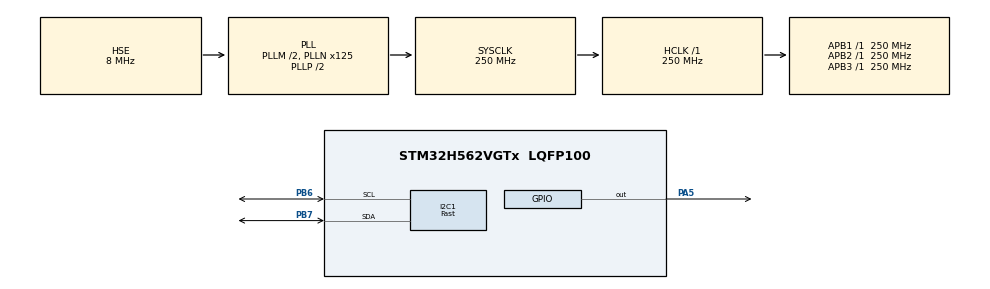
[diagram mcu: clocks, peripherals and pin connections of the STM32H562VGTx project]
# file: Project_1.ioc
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BOOTPATH.BootPathName=LEGACY
BOOTPATH.UserSelectedBootPath=LEGACY
CORTEX_M33_NS.Number-Cortex_Memory_Protection_Unit_Region0_OTP_RO_AREAS_Settings=MPU_REGION_NUMBER0
CORTEX_M33_NS.default_mode_Activation=1
CORTEX_M33_NS.userName=CORTEX_M33
I2C1.I2C_Speed_Mode=I2C_Fast
I2C1.Timing=0x10C043E5
Mcu.Family=STM32H5
Mcu.Name=STM32H562VGTx
Mcu.Package=LQFP100
NVIC.PriorityGroup=NVIC_PRIORITYGROUP_4
PA13(JTMS/SWDIO).Mode=Trace_Asynchronous_SW
PA13(JTMS/SWDIO).Signal=DEBUG_JTMS-SWDIO
PA14(JTCK/SWCLK).Mode=Trace_Asynchronous_SW
PA14(JTCK/SWCLK).Signal=DEBUG_JTCK-SWCLK
PA5.GPIO_Speed=GPIO_SPEED_FREQ_MEDIUM
PA5.Signal=GPIO_Output
PB3(JTDO/TRACESWO).Mode=Trace_Asynchronous_SW
PB3(JTDO/TRACESWO).Signal=DEBUG_JTDO-SWO
PB6.Mode=I2C
PB6.Signal=I2C1_SCL
PB7.Mode=I2C
PB7.Signal=I2C1_SDA
PH0-OSC_IN(PH0).Mode=HSE-External-Oscillator
PH0-OSC_IN(PH0).Signal=RCC_OSC_IN
PH1-OSC_OUT(PH1).Mode=HSE-External-Oscillator
PH1-OSC_OUT(PH1).Signal=RCC_OSC_OUT
ProjectManager.HeapSize=0x2000
ProjectManager.StackSize=0x4000
ProjectManager.TargetToolchain=STM32CubeIDE
RCC.ADCFreq_Value=250000000
RCC.AHBFreq_Value=250000000
RCC.APB1Freq_Value=250000000
RCC.APB1TimFreq_Value=250000000
RCC.APB2Freq_Value=250000000
RCC.APB2TimFreq_Value=250000000
RCC.APB3Freq_Value=250000000
RCC.CSI_VALUE=4000000
RCC.CortexFreq_Value=250000000
RCC.EPOD_VALUE=8000000
RCC.HCLKFreq_Value=250000000
RCC.HSE_VALUE=8000000
RCC.HSI48_VALUE=48000000
RCC.HSI_VALUE=64000000
RCC.LSE_VALUE=32768
RCC.LSIRC_VALUE=32000
RCC.PLLM=2
RCC.PLLN=125
RCC.PLLSourceVirtual=RCC_PLL1_SOURCE_HSE
RCC.SYSCLKFreq_VALUE=250000000
RCC.SYSCLKSource=RCC_SYSCLKSOURCE_PLLCLK
RCC.USBFreq_Value=48000000
RCC.VCOOutputFreq_Value=500000000
VP_BOOTPATH_VS_BOOTPATH.Mode=BP_Activate
VP_CORTEX_M33_NS_VS_Hclk.Mode=Hclk_Mode
VP_ICACHE_VS_ICACHE.Mode=DirectMappedCache
VP_MEMORYMAP_VS_MEMORYMAP.Mode=CurAppReg
VP_PWR_VS_LPOM.Mode=PowerOptimisation
VP_PWR_VS_SECSignals.Mode=Security/Privilege
board=custom

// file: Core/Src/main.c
/* USER CODE BEGIN Header */
/**
  ******************************************************************************
  * @file           : main.c
  * @brief          : Main program body
  ******************************************************************************
  * @attention
  *
  * Copyright (c) 2026 STMicroelectronics.
  * All rights reserved.
  *
  * This software is licensed under terms that can be found in the LICENSE file
  * in the root directory of this software component.
  * If no LICENSE file comes with this software, it is provided AS-IS.
  *
  ******************************************************************************
  */
/* USER CODE END Header */
#include "main.h"

/* USER CODE BEGIN Includes */
#include "bobik/bobik.h"
/* USER CODE END Includes */

I2C_HandleTypeDef hi2c1;

void SystemClock_Config(void);
static void MPU_Config(void);
static void MX_GPIO_Init(void);
static void MX_ICACHE_Init(void);
static void MX_I2C1_Init(void);

int main(void)
{

  /* MCU Configuration--------------------------------------------------------*/

  /* MPU Configuration--------------------------------------------------------*/
  MPU_Config();

  /* Reset of all peripherals, Initializes the Flash interface and the Systick. */
  HAL_Init();

  /* Configure the system clock */
  SystemClock_Config();

  /* Initialize all configured peripherals */
  MX_GPIO_Init();
  MX_ICACHE_Init();
  MX_I2C1_Init();
  /* USER CODE BEGIN 2 */
  bobik_start();
  oled_init();
  oled_fill();
  /* USER CODE END 2 */

  /* Infinite loop */
  while (1)
  {

  }
}

void SystemClock_Config(void)
{
  RCC_OscInitTypeDef RCC_OscInitStruct = {0};
  RCC_ClkInitTypeDef RCC_ClkInitStruct = {0};

  /** Configure the main internal regulator output voltage
  */
  __HAL_PWR_VOLTAGESCALING_CONFIG(PWR_REGULATOR_VOLTAGE_SCALE0);

  while(!__HAL_PWR_GET_FLAG(PWR_FLAG_VOSRDY)) {}

  /** Initializes the RCC Oscillators according to the specified parameters
  * in the RCC_OscInitTypeDef structure.
  */
  RCC_OscInitStruct.OscillatorType = RCC_OSCILLATORTYPE_HSE;
  RCC_OscInitStruct.HSEState = RCC_HSE_ON;
  RCC_OscInitStruct.PLL.PLLState = RCC_PLL_ON;
  RCC_OscInitStruct.PLL.PLLSource = RCC_PLL1_SOURCE_HSE;
  RCC_OscInitStruct.PLL.PLLM = 2;
  RCC_OscInitStruct.PLL.PLLN = 125;
  RCC_OscInitStruct.PLL.PLLP = 2;
  RCC_OscInitStruct.PLL.PLLQ = 2;
  RCC_OscInitStruct.PLL.PLLR = 2;
  RCC_OscInitStruct.PLL.PLLRGE = RCC_PLL1_VCIRANGE_2;
  RCC_OscInitStruct.PLL.PLLVCOSEL = RCC_PLL1_VCORANGE_WIDE;
  RCC_OscInitStruct.PLL.PLLFRACN = 0;
  if (HAL_RCC_OscConfig(&RCC_OscInitStruct) != HAL_OK)
  {
    Error_Handler();
  }

  /** Initializes the CPU, AHB and APB buses clocks
  */
  RCC_ClkInitStruct.ClockType = RCC_CLOCKTYPE_HCLK|RCC_CLOCKTYPE_SYSCLK
                              |RCC_CLOCKTYPE_PCLK1|RCC_CLOCKTYPE_PCLK2
                              |RCC_CLOCKTYPE_PCLK3;
  RCC_ClkInitStruct.SYSCLKSource = RCC_SYSCLKSOURCE_PLLCLK;
  RCC_ClkInitStruct.AHBCLKDivider = RCC_SYSCLK_DIV1;
  RCC_ClkInitStruct.APB1CLKDivider = RCC_HCLK_DIV1;
  RCC_ClkInitStruct.APB2CLKDivider = RCC_HCLK_DIV1;
  RCC_ClkInitStruct.APB3CLKDivider = RCC_HCLK_DIV1;

  if (HAL_RCC_ClockConfig(&RCC_ClkInitStruct, FLASH_LATENCY_5) != HAL_OK)
  {
    Error_Handler();
  }

  /** Configure the programming delay
  */
  __HAL_FLASH_SET_PROGRAM_DELAY(FLASH_PROGRAMMING_DELAY_2);
}

static void MX_I2C1_Init(void)
{

  hi2c1.Instance = I2C1;
  hi2c1.Init.Timing = 0x10C043E5;
  hi2c1.Init.OwnAddress1 = 0;
  hi2c1.Init.AddressingMode = I2C_ADDRESSINGMODE_7BIT;
  hi2c1.Init.DualAddressMode = I2C_DUALADDRESS_DISABLE;
  hi2c1.Init.OwnAddress2 = 0;
  hi2c1.Init.OwnAddress2Masks = I2C_OA2_NOMASK;
  hi2c1.Init.GeneralCallMode = I2C_GENERALCALL_DISABLE;
  hi2c1.Init.NoStretchMode = I2C_NOSTRETCH_DISABLE;
  if (HAL_I2C_Init(&hi2c1) != HAL_OK)
  {
    Error_Handler();
  }

  /** Configure Analogue filter
  */
  if (HAL_I2CEx_ConfigAnalogFilter(&hi2c1, I2C_ANALOGFILTER_ENABLE) != HAL_OK)
  {
    Error_Handler();
  }

  /** Configure Digital filter
  */
  if (HAL_I2CEx_ConfigDigitalFilter(&hi2c1, 0) != HAL_OK)
  {
    Error_Handler();
  }

}

static void MX_ICACHE_Init(void)
{

  /** Enable instruction cache in 1-way (direct mapped cache)
  */
  if (HAL_ICACHE_ConfigAssociativityMode(ICACHE_1WAY) != HAL_OK)
  {
    Error_Handler();
  }
  if (HAL_ICACHE_Enable() != HAL_OK)
  {
    Error_Handler();
  }

}

static void MX_GPIO_Init(void)
{
  GPIO_InitTypeDef GPIO_InitStruct = {0};

  /* GPIO Ports Clock Enable */
  __HAL_RCC_GPIOH_CLK_ENABLE();
  __HAL_RCC_GPIOA_CLK_ENABLE();
  __HAL_RCC_GPIOB_CLK_ENABLE();

  /*Configure GPIO pin Output Level */
  HAL_GPIO_WritePin(GPIOA, GPIO_PIN_5, GPIO_PIN_RESET);

  /*Configure GPIO pin : PA5 */
  GPIO_InitStruct.Pin = GPIO_PIN_5;
  GPIO_InitStruct.Mode = GPIO_MODE_OUTPUT_PP;
  GPIO_InitStruct.Pull = GPIO_NOPULL;
  GPIO_InitStruct.Speed = GPIO_SPEED_FREQ_MEDIUM;
  HAL_GPIO_Init(GPIOA, &GPIO_InitStruct);

  /*Configure GPIO pin : PA13 */
  GPIO_InitStruct.Pin = GPIO_PIN_13;
  GPIO_InitStruct.Mode = GPIO_MODE_AF_PP;
  GPIO_InitStruct.Pull = GPIO_PULLUP;
  GPIO_InitStruct.Speed = GPIO_SPEED_FREQ_LOW;
  GPIO_InitStruct.Alternate = GPIO_AF0_TRACE;
  HAL_GPIO_Init(GPIOA, &GPIO_InitStruct);

  /*Configure GPIO pin : PB3 */
  GPIO_InitStruct.Pin = GPIO_PIN_3;
  GPIO_InitStruct.Mode = GPIO_MODE_AF_PP;
  GPIO_InitStruct.Pull = GPIO_NOPULL;
  GPIO_InitStruct.Speed = GPIO_SPEED_FREQ_LOW;
  GPIO_InitStruct.Alternate = GPIO_AF0_TRACE;
  HAL_GPIO_Init(GPIOB, &GPIO_InitStruct);

}

 /* MPU Configuration */

void MPU_Config(void)
{
  MPU_Region_InitTypeDef MPU_InitStruct = {0};
  MPU_Attributes_InitTypeDef MPU_AttributesInit = {0};

  /* Disables the MPU */
  HAL_MPU_Disable();

  /** Initializes and configures the Region 0 and the memory to be protected
  */
  MPU_InitStruct.Enable = MPU_REGION_ENABLE;
  MPU_InitStruct.Number = MPU_REGION_NUMBER0;
  MPU_InitStruct.BaseAddress = 0x08FFF000;
  MPU_InitStruct.LimitAddress = 0x08FFFFFF;
  MPU_InitStruct.AttributesIndex = MPU_ATTRIBUTES_NUMBER0;
  MPU_InitStruct.AccessPermission = MPU_REGION_ALL_RO;
  MPU_InitStruct.DisableExec = MPU_INSTRUCTION_ACCESS_DISABLE;
  MPU_InitStruct.IsShareable = MPU_ACCESS_NOT_SHAREABLE;

  HAL_MPU_ConfigRegion(&MPU_InitStruct);

  /** Initializes and configures the Attribute 0 and the memory to be protected
  */
  MPU_AttributesInit.Number = MPU_ATTRIBUTES_NUMBER0;
  MPU_AttributesInit.Attributes = INNER_OUTER(MPU_NOT_CACHEABLE);

  HAL_MPU_ConfigMemoryAttributes(&MPU_AttributesInit);
  /* Enables the MPU */
  HAL_MPU_Enable(MPU_PRIVILEGED_DEFAULT);

}

void Error_Handler(void)
{
  __disable_irq();
  while (1)
  {
  }
}
